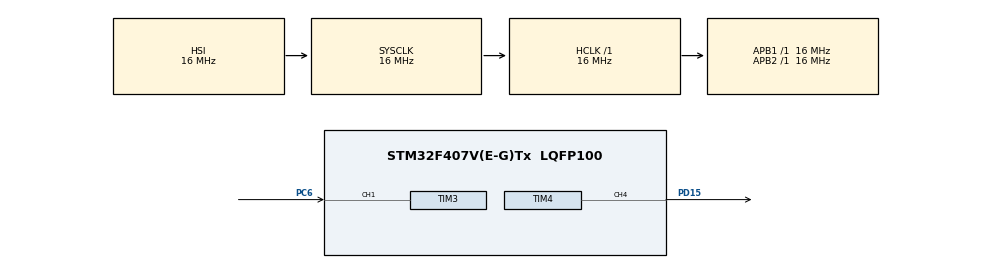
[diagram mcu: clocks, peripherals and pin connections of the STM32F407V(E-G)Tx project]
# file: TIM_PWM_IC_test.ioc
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Mcu.Family=STM32F4
Mcu.Name=STM32F407V(E-G)Tx
Mcu.Package=LQFP100
NVIC.PriorityGroup=NVIC_PRIORITYGROUP_4
NVIC.TIM3_IRQn=true\:0\:0\:false\:false\:true\:true\:true\:true
PA13.Mode=Serial_Wire
PA13.Signal=SYS_JTMS-SWDIO
PA14.Mode=Serial_Wire
PA14.Signal=SYS_JTCK-SWCLK
PC6.Signal=S_TIM3_CH1
PD15.Signal=S_TIM4_CH4
ProjectManager.HeapSize=0x200
ProjectManager.StackSize=0x400
ProjectManager.TargetToolchain=MDK-ARM V5.32
RCC.AHBFreq_Value=16000000
RCC.APB1Freq_Value=16000000
RCC.APB2Freq_Value=16000000
RCC.CortexFreq_Value=16000000
RCC.HSE_VALUE=25000000
RCC.HSI_VALUE=16000000
RCC.LSE_VALUE=32768
RCC.SYSCLKFreq_VALUE=16000000
RCC.VCOOutputFreq_Value=192000000
SH.S_TIM3_CH1.0=TIM3_CH1,Input_Capture1_from_TI1
SH.S_TIM4_CH4.0=TIM4_CH4,PWM Generation4 CH4
TIM3.Channel-Input_Capture1_from_TI1=TIM_CHANNEL_1
TIM3.Channel-Input_Capture2_from_TI1_63=TIM_CHANNEL_2
TIM3.Prescaler=16-1
TIM4.Channel-PWM\ Generation4\ CH4=TIM_CHANNEL_4
TIM4.Period=1000-1
TIM4.Prescaler=16-1
TIM4.Pulse-PWM\ Generation4\ CH4=200-1
VP_TIM3_VS_ClockSourceINT.Mode=Internal
VP_TIM3_VS_indirect_ch1.Mode=Input_Capture2_from_TI1_63
VP_TIM4_VS_ClockSourceINT.Mode=Internal
board=custom

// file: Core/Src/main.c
/* USER CODE BEGIN Header */
/**
  ******************************************************************************
  * @file           : main.c
  * @brief          : Main program body
  ******************************************************************************
  * @attention
  *
  * Copyright (c) 2023 STMicroelectronics.
  * All rights reserved.
  *
  * This software is licensed under terms that can be found in the LICENSE file
  * in the root directory of this software component.
  * If no LICENSE file comes with this software, it is provided AS-IS.
  *
  ******************************************************************************
  */
/* USER CODE END Header */
#include "main.h"
#include "tim.h"
#include "gpio.h"

void SystemClock_Config(void);

int main(void)
{

  /* MCU Configuration--------------------------------------------------------*/

  /* Reset of all peripherals, Initializes the Flash interface and the Systick. */
  HAL_Init();

  /* Configure the system clock */
  SystemClock_Config();

  /* Initialize all configured peripherals */
  MX_GPIO_Init();
  MX_TIM3_Init();
  MX_TIM4_Init();
  /* USER CODE BEGIN 2 */
		HAL_TIM_Base_Start(&htim4);
		HAL_TIM_PWM_Start(&htim4, TIM_CHANNEL_4);

		HAL_TIM_Base_Start(&htim3);
		HAL_TIM_IC_Start_IT(&htim3, TIM_CHANNEL_1);
  /* USER CODE END 2 */

  /* Infinite loop */
  while (1)
  {

  }
}

void SystemClock_Config(void)
{
  RCC_OscInitTypeDef RCC_OscInitStruct = {0};
  RCC_ClkInitTypeDef RCC_ClkInitStruct = {0};

  /** Configure the main internal regulator output voltage
  */
  __HAL_RCC_PWR_CLK_ENABLE();
  __HAL_PWR_VOLTAGESCALING_CONFIG(PWR_REGULATOR_VOLTAGE_SCALE1);

  /** Initializes the RCC Oscillators according to the specified parameters
  * in the RCC_OscInitTypeDef structure.
  */
  RCC_OscInitStruct.OscillatorType = RCC_OSCILLATORTYPE_HSI;
  RCC_OscInitStruct.HSIState = RCC_HSI_ON;
  RCC_OscInitStruct.HSICalibrationValue = RCC_HSICALIBRATION_DEFAULT;
  RCC_OscInitStruct.PLL.PLLState = RCC_PLL_NONE;
  if (HAL_RCC_OscConfig(&RCC_OscInitStruct) != HAL_OK)
  {
    Error_Handler();
  }

  /** Initializes the CPU, AHB and APB buses clocks
  */
  RCC_ClkInitStruct.ClockType = RCC_CLOCKTYPE_HCLK|RCC_CLOCKTYPE_SYSCLK
                              |RCC_CLOCKTYPE_PCLK1|RCC_CLOCKTYPE_PCLK2;
  RCC_ClkInitStruct.SYSCLKSource = RCC_SYSCLKSOURCE_HSI;
  RCC_ClkInitStruct.AHBCLKDivider = RCC_SYSCLK_DIV1;
  RCC_ClkInitStruct.APB1CLKDivider = RCC_HCLK_DIV1;
  RCC_ClkInitStruct.APB2CLKDivider = RCC_HCLK_DIV1;

  if (HAL_RCC_ClockConfig(&RCC_ClkInitStruct, FLASH_LATENCY_0) != HAL_OK)
  {
    Error_Handler();
  }
}

void Error_Handler(void)
{
  __disable_irq();
  while (1)
  {
  }
}
